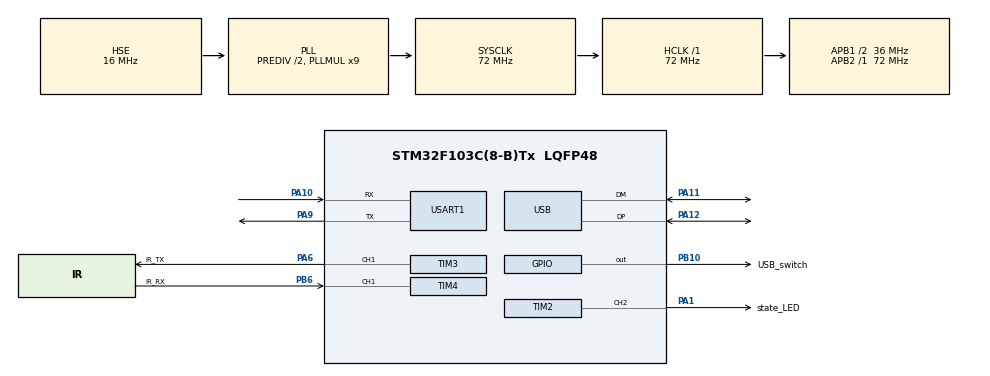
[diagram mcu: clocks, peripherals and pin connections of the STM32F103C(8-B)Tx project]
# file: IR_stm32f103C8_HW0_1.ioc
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Mcu.Family=STM32F1
Mcu.Name=STM32F103C(8-B)Tx
Mcu.Package=LQFP48
NVIC.PriorityGroup=NVIC_PRIORITYGROUP_4
NVIC.TIM4_IRQn=true\:0\:0\:false\:false\:true
NVIC.USART1_IRQn=true\:0\:0\:false\:false\:true
NVIC.USB_LP_CAN1_RX0_IRQn=true\:0\:0\:false\:false\:true
PA1.GPIO_Label=state_LED
PA1.Signal=S_TIM2_CH2
PA10.Mode=Asynchronous
PA10.Signal=USART1_RX
PA11.Mode=Device
PA11.Signal=USB_DM
PA12.Mode=Device
PA12.Signal=USB_DP
PA13.Mode=Serial_Wire
PA13.Signal=SYS_JTMS-SWDIO
PA14.Mode=Serial_Wire
PA14.Signal=SYS_JTCK-SWCLK
PA6.GPIO_Label=IR_TX
PA6.Signal=S_TIM3_CH1
PA9.Mode=Asynchronous
PA9.Signal=USART1_TX
PB10.GPIO_Label=USB_switch
PB10.PinState=GPIO_PIN_SET
PB10.Signal=GPIO_Output
PB6.GPIO_Label=IR_RX
PB6.Signal=S_TIM4_CH1
PD0-OSC_IN.Mode=HSE-External-Oscillator
PD0-OSC_IN.Signal=RCC_OSC_IN
PD1-OSC_OUT.Mode=HSE-External-Oscillator
PD1-OSC_OUT.Signal=RCC_OSC_OUT
ProjectManager.HeapSize=0x200
ProjectManager.StackSize=0x1000
ProjectManager.TargetToolchain=EWARM
RCC.AHBFreq_Value=72000000
RCC.APB1CLKDivider=RCC_HCLK_DIV2
RCC.APB1Freq_Value=36000000
RCC.APB1TimFreq_Value=72000000
RCC.APB2Freq_Value=72000000
RCC.APB2TimFreq_Value=72000000
RCC.HCLKFreq_Value=72000000
RCC.HSEDivPLL=RCC_HSE_PREDIV_DIV2
RCC.HSE_VALUE=16000000
RCC.PLLMUL=RCC_PLL_MUL9
RCC.SYSCLKFreq_VALUE=72000000
RCC.SYSCLKSource=RCC_SYSCLKSOURCE_PLLCLK
RCC.USBFreq_Value=48000000
RCC.USBPrescaler=RCC_USBCLKSOURCE_PLL_DIV1_5
SH.S_TIM2_CH2.0=TIM2_CH2,PWM Generation2 CH2
SH.S_TIM3_CH1.0=TIM3_CH1,PWM Generation1 CH1
SH.S_TIM4_CH1.0=TIM4_CH1,Input_Capture1_from_TI1
TIM1.Period=7200
TIM2.Channel-PWM\ Generation2\ CH2=TIM_CHANNEL_2
TIM2.Period=200
TIM2.Prescaler=20000-1
TIM2.Pulse-PWM\ Generation2\ CH2=100
TIM3.Channel-PWM\ Generation1\ CH1=TIM_CHANNEL_1
TIM3.Period=1800
TIM3.Pulse-PWM\ Generation1\ CH1=600
TIM4.Channel-Input_Capture1_from_TI1=TIM_CHANNEL_1
TIM4.ICPolarity_CH1=TIM_INPUTCHANNELPOLARITY_FALLING
TIM4.Period=100
TIM4.Prescaler=7200-1
USART1.VirtualMode=VM_ASYNC
USB.ep0_mps=DEP0CTL_MPS_64
USB_DEVICE.CLASS_NAME_FS=CDC
USB_DEVICE.VirtualMode=Cdc
USB_DEVICE.VirtualModeFS=Cdc_FS
VP_CRC_VS_CRC.Mode=CRC_Activate
VP_TIM1_VS_ClockSourceINT.Mode=Internal
VP_USB_DEVICE_VS_USB_DEVICE_CDC_FS.Mode=CDC_FS
board=IR_stm32f103C8_HW0_1

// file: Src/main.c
/**
  ******************************************************************************
  * File Name          : main.c
  * Description        : Main program body
  ******************************************************************************
  * This notice applies to any and all portions of this file
  * that are not between comment pairs USER CODE BEGIN and
  * USER CODE END. Other portions of this file, whether
  * inserted by the user or by software development tools
  * are owned by their respective copyright owners.
  *
  * Copyright (c) 2017 STMicroelectronics International N.V.
  * All rights reserved.
  *
  * Redistribution and use in source and binary forms, with or without
  * modification, are permitted, provided that the following conditions are met:
  *
  * 1. Redistribution of source code must retain the above copyright notice,
  *    this list of conditions and the following disclaimer.
  * 2. Redistributions in binary form must reproduce the above copyright notice,
  *    this list of conditions and the following disclaimer in the documentation
  *    and/or other materials provided with the distribution.
  * 3. Neither the name of STMicroelectronics nor the names of other
  *    contributors to this software may be used to endorse or promote products
  *    derived from this software without specific written permission.
  * 4. This software, including modifications and/or derivative works of this
  *    software, must execute solely and exclusively on microcontroller or
  *    microprocessor devices manufactured by or for STMicroelectronics.
  * 5. Redistribution and use of this software other than as permitted under
  *    this license is void and will automatically terminate your rights under
  *    this license.
  *
  * THIS SOFTWARE IS PROVIDED BY STMICROELECTRONICS AND CONTRIBUTORS "AS IS"
  * AND ANY EXPRESS, IMPLIED OR STATUTORY WARRANTIES, INCLUDING, BUT NOT
  * LIMITED TO, THE IMPLIED WARRANTIES OF MERCHANTABILITY, FITNESS FOR A
  * PARTICULAR PURPOSE AND NON-INFRINGEMENT OF THIRD PARTY INTELLECTUAL PROPERTY
  * RIGHTS ARE DISCLAIMED TO THE FULLEST EXTENT PERMITTED BY LAW. IN NO EVENT
  * SHALL STMICROELECTRONICS OR CONTRIBUTORS BE LIABLE FOR ANY DIRECT, INDIRECT,
  * INCIDENTAL, SPECIAL, EXEMPLARY, OR CONSEQUENTIAL DAMAGES (INCLUDING, BUT NOT
  * LIMITED TO, PROCUREMENT OF SUBSTITUTE GOODS OR SERVICES; LOSS OF USE, DATA,
  * OR PROFITS; OR BUSINESS INTERRUPTION) HOWEVER CAUSED AND ON ANY THEORY OF
  * LIABILITY, WHETHER IN CONTRACT, STRICT LIABILITY, OR TORT (INCLUDING
  * NEGLIGENCE OR OTHERWISE) ARISING IN ANY WAY OUT OF THE USE OF THIS SOFTWARE,
  * EVEN IF ADVISED OF THE POSSIBILITY OF SUCH DAMAGE.
  *
  ******************************************************************************
  */
#include "main.h"
#include "stm32f1xx_hal.h"
#include "crc.h"
#include "tim.h"
#include "usart.h"
#include "usb_device.h"
#include "gpio.h"

/* USER CODE BEGIN Includes */
#include "IR.h"
#include "protocol.h"
#include "IR_RX.h"
#include "upgrade.h"
#include "eeprom.h"
/* USER CODE END Includes */

/* USER CODE BEGIN PV */
/* Private variables ---------------------------------------------------------*/

/* USER CODE END PV */

void SystemClock_Config(void);

/* USER CODE BEGIN PFP */
/* Private function prototypes -----------------------------------------------*/

/* USER CODE END PFP */

int main(void)
{

  /* USER CODE BEGIN 1 */
  SCB->VTOR = APP_ADDR;

  /* USER CODE END 1 */

  /* MCU Configuration----------------------------------------------------------*/

  /* Reset of all peripherals, Initializes the Flash interface and the Systick. */
  HAL_Init();

  /* Configure the system clock */
  SystemClock_Config();

  /* Initialize all configured peripherals */
  MX_GPIO_Init();
  MX_USART1_UART_Init();
  MX_CRC_Init();
  MX_TIM1_Init();
  MX_TIM2_Init();
  MX_TIM3_Init();
  MX_TIM4_Init();
  MX_USB_DEVICE_Init();

  /* USER CODE BEGIN 2 */
  uart_init();
  IR_init();
  uart_config_wifi();
  /* USER CODE END 2 */

  /* Infinite loop */
  /* USER CODE BEGIN WHILE */
  while (1)
  {
    IR_loop();
    protocol_loop();
    eeprom_loop();
    uart_loop();

  /* USER CODE END WHILE */

  }

}

/** System Clock Configuration
*/
void SystemClock_Config(void)
{

  RCC_OscInitTypeDef RCC_OscInitStruct;
  RCC_ClkInitTypeDef RCC_ClkInitStruct;
  RCC_PeriphCLKInitTypeDef PeriphClkInit;

    /**Initializes the CPU, AHB and APB busses clocks
    */
  RCC_OscInitStruct.OscillatorType = RCC_OSCILLATORTYPE_HSE;
  RCC_OscInitStruct.HSEState = RCC_HSE_ON;
  RCC_OscInitStruct.HSEPredivValue = RCC_HSE_PREDIV_DIV2;
  RCC_OscInitStruct.HSIState = RCC_HSI_ON;
  RCC_OscInitStruct.PLL.PLLState = RCC_PLL_ON;
  RCC_OscInitStruct.PLL.PLLSource = RCC_PLLSOURCE_HSE;
  RCC_OscInitStruct.PLL.PLLMUL = RCC_PLL_MUL9;
  if (HAL_RCC_OscConfig(&RCC_OscInitStruct) != HAL_OK)
  {
    _Error_Handler(__FILE__, __LINE__);
  }

    /**Initializes the CPU, AHB and APB busses clocks
    */
  RCC_ClkInitStruct.ClockType = RCC_CLOCKTYPE_HCLK|RCC_CLOCKTYPE_SYSCLK
                              |RCC_CLOCKTYPE_PCLK1|RCC_CLOCKTYPE_PCLK2;
  RCC_ClkInitStruct.SYSCLKSource = RCC_SYSCLKSOURCE_PLLCLK;
  RCC_ClkInitStruct.AHBCLKDivider = RCC_SYSCLK_DIV1;
  RCC_ClkInitStruct.APB1CLKDivider = RCC_HCLK_DIV2;
  RCC_ClkInitStruct.APB2CLKDivider = RCC_HCLK_DIV1;

  if (HAL_RCC_ClockConfig(&RCC_ClkInitStruct, FLASH_LATENCY_2) != HAL_OK)
  {
    _Error_Handler(__FILE__, __LINE__);
  }

  PeriphClkInit.PeriphClockSelection = RCC_PERIPHCLK_USB;
  PeriphClkInit.UsbClockSelection = RCC_USBCLKSOURCE_PLL_DIV1_5;
  if (HAL_RCCEx_PeriphCLKConfig(&PeriphClkInit) != HAL_OK)
  {
    _Error_Handler(__FILE__, __LINE__);
  }

    /**Configure the Systick interrupt time
    */
  HAL_SYSTICK_Config(HAL_RCC_GetHCLKFreq()/1000);

    /**Configure the Systick
    */
  HAL_SYSTICK_CLKSourceConfig(SYSTICK_CLKSOURCE_HCLK);

  /* SysTick_IRQn interrupt configuration */
  HAL_NVIC_SetPriority(SysTick_IRQn, 2, 0);
}

void _Error_Handler(char * file, int line)
{
  while(1)
  {
  }
}

/************************ (C) COPYRIGHT STMicroelectronics *****END OF FILE****/
